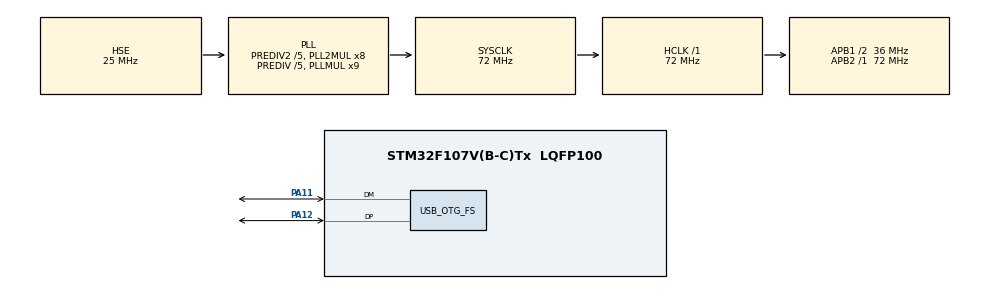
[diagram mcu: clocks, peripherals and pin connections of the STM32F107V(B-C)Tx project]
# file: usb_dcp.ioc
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Mcu.Family=STM32F1
Mcu.Name=STM32F107V(B-C)Tx
Mcu.Package=LQFP100
NVIC.OTG_FS_IRQn=true\:0\:0\:false\:false\:true\:false\:true
NVIC.PriorityGroup=NVIC_PRIORITYGROUP_4
OSC_IN.Mode=HSE-External-Oscillator
OSC_IN.Signal=RCC_OSC_IN
OSC_OUT.Mode=HSE-External-Oscillator
OSC_OUT.Signal=RCC_OSC_OUT
PA11.Mode=Device_Only
PA11.Signal=USB_OTG_FS_DM
PA12.Mode=Device_Only
PA12.Signal=USB_OTG_FS_DP
PA13.Mode=Trace_Asynchronous_SW
PA13.Signal=SYS_JTMS-SWDIO
PA14.Mode=Trace_Asynchronous_SW
PA14.Signal=SYS_JTCK-SWCLK
PB3.Mode=Trace_Asynchronous_SW
PB3.Signal=SYS_TRACESWO
ProjectManager.HeapSize=0x200
ProjectManager.StackSize=0x400
ProjectManager.TargetToolchain=TrueSTUDIO
RCC.AHBFreq_Value=72000000
RCC.APB1CLKDivider=RCC_HCLK_DIV2
RCC.APB1Freq_Value=36000000
RCC.APB1TimFreq_Value=72000000
RCC.APB2Freq_Value=72000000
RCC.APB2TimFreq_Value=72000000
RCC.HCLKFreq_Value=72000000
RCC.HSEDivPLL=RCC_HSE_PREDIV_DIV5
RCC.HSE_VALUE=25000000
RCC.PLLMUL=RCC_PLL_MUL9
RCC.PLLSourceVirtual=RCC_PLLSOURCE_HSE
RCC.Prediv1Source=RCC_PREDIV1_SOURCE_PLL2
RCC.Prediv2=RCC_HSE_PREDIV2_DIV5
RCC.SYSCLKFreq_VALUE=72000000
RCC.SYSCLKSource=RCC_SYSCLKSOURCE_PLLCLK
RCC.USBFreq_Value=48000000
USB_DEVICE.CLASS_NAME_FS=CDC
USB_DEVICE.VirtualMode=Cdc
USB_DEVICE.VirtualModeFS=Cdc_FS
USB_OTG_FS.VirtualMode=Device_Only
VP_USB_DEVICE_VS_USB_DEVICE_CDC_FS.Mode=CDC_FS
board=custom

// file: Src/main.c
/* USER CODE BEGIN Header */
/**
  ******************************************************************************
  * @file           : main.c
  * @brief          : Main program body
  ******************************************************************************
  * @attention
  *
  * <h2><center>&copy; Copyright (c) 2019 STMicroelectronics.
  * All rights reserved.</center></h2>
  *
  * This software component is licensed by ST under Ultimate Liberty license
  * SLA0044, the "License"; You may not use this file except in compliance with
  * the License. You may obtain a copy of the License at:
  *                             www.st.com/SLA0044
  *
  ******************************************************************************
  */
/* USER CODE END Header */

#include "main.h"
#include "usb_device.h"
#include "gpio.h"
#include "usbd_cdc_if.h"

void SystemClock_Config(void);

int main(void)
{

  /* MCU Configuration--------------------------------------------------------*/

  /* Reset of all peripherals, Initializes the Flash interface and the Systick. */
  HAL_Init();

  /* Configure the system clock */
  SystemClock_Config();

  /* Initialize all configured peripherals */
  MX_GPIO_Init();
  MX_USB_DEVICE_Init();

  /* Infinite loop */
  while (1)
  {

  }
}

void SystemClock_Config(void)
{
  RCC_OscInitTypeDef RCC_OscInitStruct = {0};
  RCC_ClkInitTypeDef RCC_ClkInitStruct = {0};
  RCC_PeriphCLKInitTypeDef PeriphClkInit = {0};

  /** Initializes the CPU, AHB and APB busses clocks
  */
  RCC_OscInitStruct.OscillatorType = RCC_OSCILLATORTYPE_HSE;
  RCC_OscInitStruct.HSEState = RCC_HSE_ON;
  RCC_OscInitStruct.HSEPredivValue = RCC_HSE_PREDIV_DIV5;
  RCC_OscInitStruct.HSIState = RCC_HSI_ON;
  RCC_OscInitStruct.Prediv1Source = RCC_PREDIV1_SOURCE_PLL2;
  RCC_OscInitStruct.PLL.PLLState = RCC_PLL_ON;
  RCC_OscInitStruct.PLL.PLLSource = RCC_PLLSOURCE_HSE;
  RCC_OscInitStruct.PLL.PLLMUL = RCC_PLL_MUL9;
  RCC_OscInitStruct.PLL2.PLL2State = RCC_PLL2_ON;
  RCC_OscInitStruct.PLL2.PLL2MUL = RCC_PLL2_MUL8;
  RCC_OscInitStruct.PLL2.HSEPrediv2Value = RCC_HSE_PREDIV2_DIV5;
  if (HAL_RCC_OscConfig(&RCC_OscInitStruct) != HAL_OK)
  {
    Error_Handler();
  }
  /** Initializes the CPU, AHB and APB busses clocks
  */
  RCC_ClkInitStruct.ClockType = RCC_CLOCKTYPE_HCLK|RCC_CLOCKTYPE_SYSCLK
                              |RCC_CLOCKTYPE_PCLK1|RCC_CLOCKTYPE_PCLK2;
  RCC_ClkInitStruct.SYSCLKSource = RCC_SYSCLKSOURCE_PLLCLK;
  RCC_ClkInitStruct.AHBCLKDivider = RCC_SYSCLK_DIV1;
  RCC_ClkInitStruct.APB1CLKDivider = RCC_HCLK_DIV2;
  RCC_ClkInitStruct.APB2CLKDivider = RCC_HCLK_DIV1;

  if (HAL_RCC_ClockConfig(&RCC_ClkInitStruct, FLASH_LATENCY_2) != HAL_OK)
  {
    Error_Handler();
  }
  PeriphClkInit.PeriphClockSelection = RCC_PERIPHCLK_USB;
  PeriphClkInit.UsbClockSelection = RCC_USBCLKSOURCE_PLL_DIV3;
  if (HAL_RCCEx_PeriphCLKConfig(&PeriphClkInit) != HAL_OK)
  {
    Error_Handler();
  }
  /** Configure the Systick interrupt time
  */
  __HAL_RCC_PLLI2S_ENABLE();
}

/* USER CODE BEGIN 4 */
void CDC_ReceiveCallBack(uint8_t* Buf, uint32_t len){
	CDC_Transmit_FS(Buf, len);
}
/* USER CODE END 4 */

void Error_Handler(void)
{
}

/************************ (C) COPYRIGHT STMicroelectronics *****END OF FILE****/
